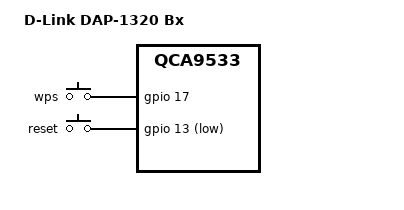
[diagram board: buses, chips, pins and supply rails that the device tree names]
// SPDX-License-Identifier: GPL-2.0-or-later OR MIT
/dts-v1/;

#include <dt-bindings/gpio/gpio.h>
#include <dt-bindings/input/input.h>

#include "qca953x.dtsi"
#include "qca9533_dlink_dap-1320.dtsi"

/ {
	model = "D-Link DAP-1320 Bx";
	compatible = "dlink,dap-1320-bx", "qca,qca9533";

	keys {
		compatible = "gpio-keys";

		wps {
			label = "wps";
			linux,code = <KEY_WPS_BUTTON>;
			gpios = <&gpio 17 GPIO_ACTIVE_HIGH>;
		};

		reset {
			label = "reset";
			linux,code = <KEY_RESTART>;
			gpios = <&gpio 13 GPIO_ACTIVE_LOW>;
		};
	};
};
